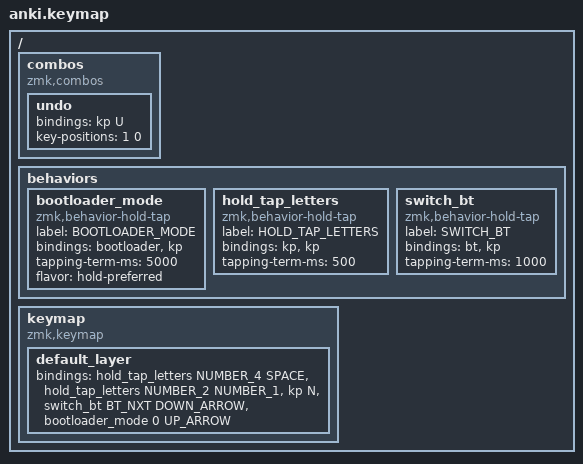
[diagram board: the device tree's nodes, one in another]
#include <behaviors.dtsi>
#include <dt-bindings/zmk/bt.h>
#include <dt-bindings/zmk/keys.h>

/ {
    combos {
        compatible = "zmk,combos";

        undo {
            bindings = <&kp U>;
            key-positions = <1 0>;
        };
    };

    behaviors {
        bootloader_mode: bootloader_mode {
            compatible = "zmk,behavior-hold-tap";
            label = "BOOTLOADER_MODE";
            bindings = <&bootloader>, <&kp>;

            #binding-cells = <2>;
            tapping-term-ms = <5000>;
            flavor = "hold-preferred";
        };

        hold_tap_letters: hold_tap_letters {
            compatible = "zmk,behavior-hold-tap";
            label = "HOLD_TAP_LETTERS";
            bindings = <&kp>, <&kp>;

            #binding-cells = <2>;
            tapping-term-ms = <500>;
        };

        switch_bt: switch_bt {
            compatible = "zmk,behavior-hold-tap";
            label = "SWITCH_BT";
            bindings = <&bt>, <&kp>;

            #binding-cells = <2>;
            tapping-term-ms = <1000>;
        };
    };

    keymap {
        compatible = "zmk,keymap";

        default_layer {
            bindings = <
&hold_tap_letters NUMBER_4 SPACE  &hold_tap_letters NUMBER_2 NUMBER_1  &kp N  &switch_bt BT_NXT DOWN_ARROW  &bootloader_mode 0 UP_ARROW
            >;
        };
    };
};
